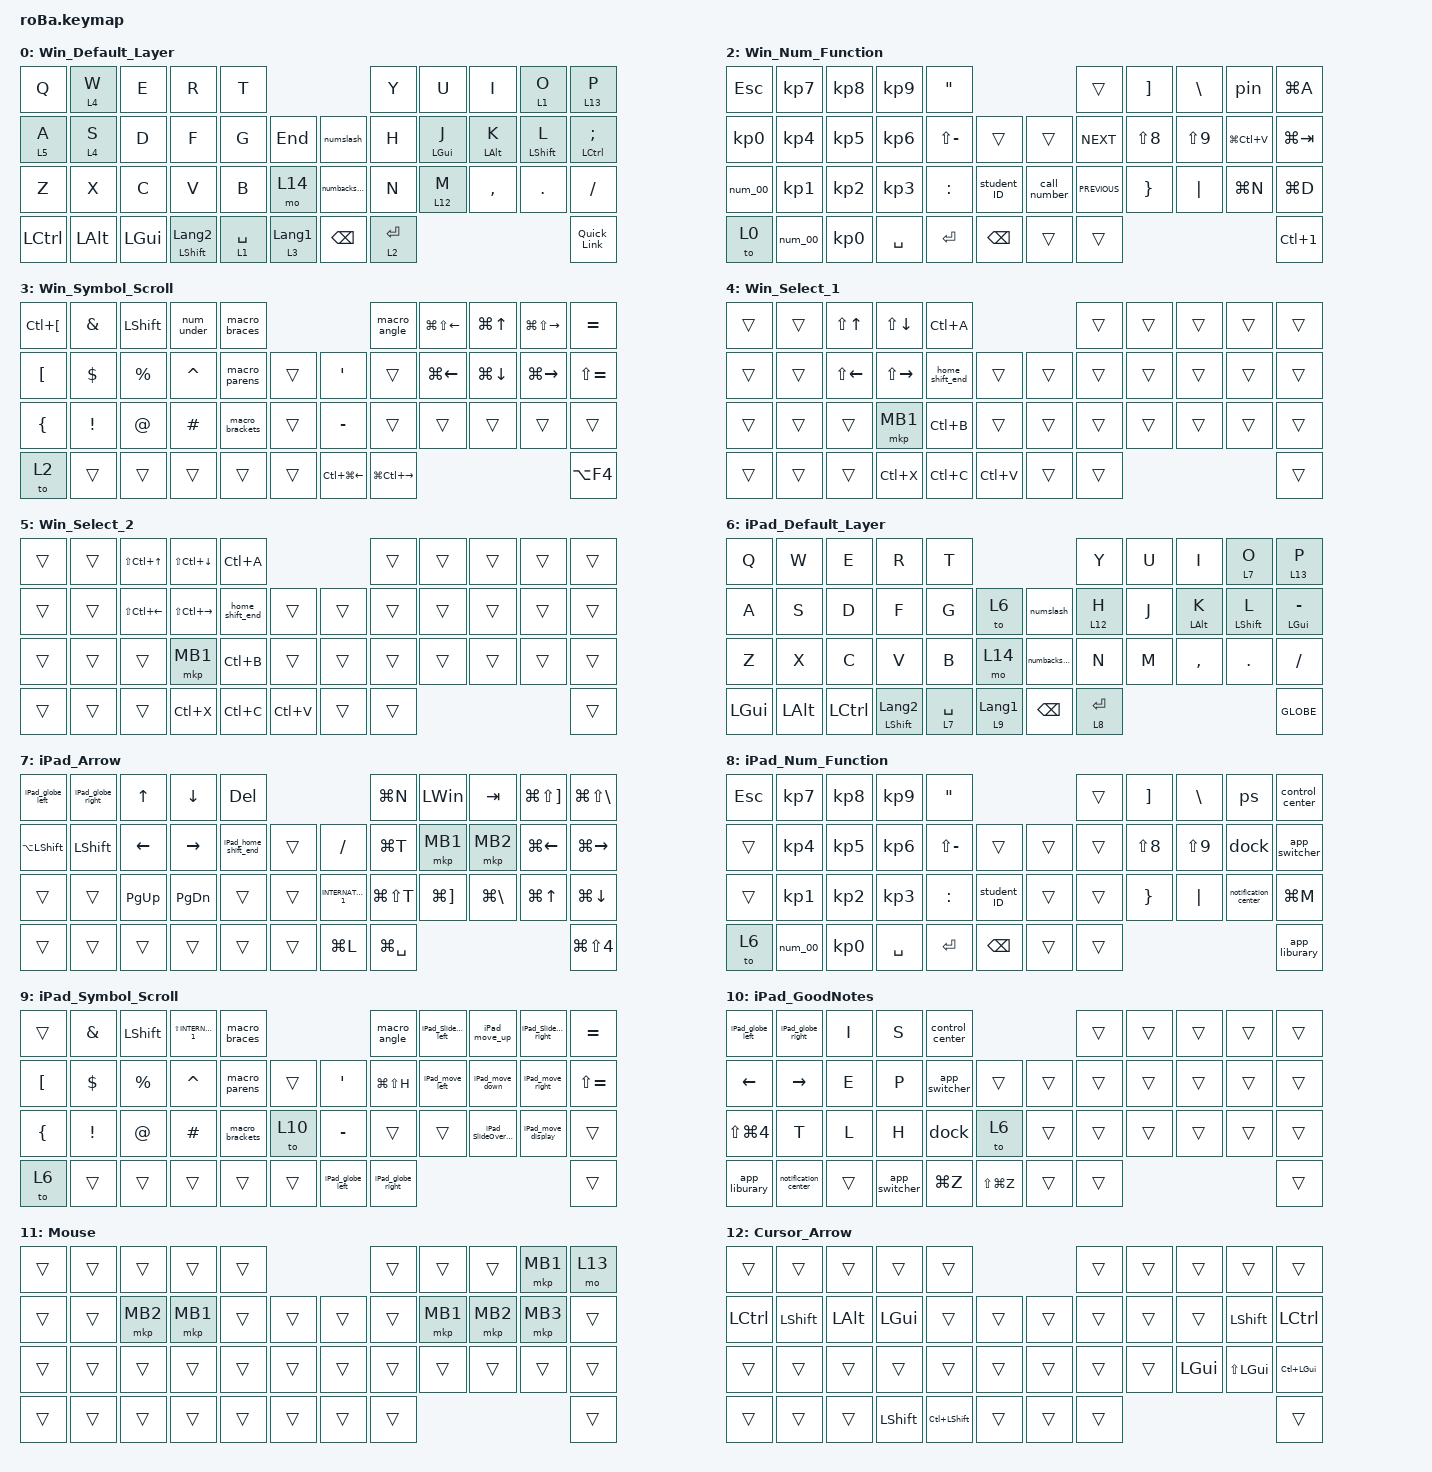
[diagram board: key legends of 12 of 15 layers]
#include <behaviors.dtsi>
#include <dt-bindings/zmk/bt.h>
#include <dt-bindings/zmk/keys.h>
#include <dt-bindings/zmk/pointing.h>

// #includeのあとのあたりにスクロール量変更の定義を追記

#define ZMK_POINTING_DEFAULT_SCRL_VAL 80

&mt {
    flavor = "balanced";
    quick-tap-ms = <0>;
};

&trackball {
    scroll-layers = <13>;

    arrows {
        layers = <12>;
        bindings =
            <&kp RIGHT_ARROW>,
            <&kp LEFT_ARROW>,
            <&kp UP_ARROW>,
            <&kp DOWN_ARROW>;

        wait-ms = <5>;
        tap-ms = <5>;
    };
};

/ {
    combos {
        compatible = "zmk,combos";

        shift_tab {
            bindings = <&kp LS(TAB)>;
            key-positions = <12 11>;
        };

        ctrl_alt_up {
            bindings = <&kp LC(LA(UP_ARROW))>;
            key-positions = <39 2>;
        };

        ctrl_alt_down {
            bindings = <&kp LC(LA(DOWN_ARROW))>;
            key-positions = <39 3>;
        };

        alt_z {
            bindings = <&kp LA(Z)>;
            key-positions = <22 23>;
        };

        left {
            bindings = <&left>;
            key-positions = <18 40>;
        };

        right {
            bindings = <&right>;
            key-positions = <19 40>;
        };

        up {
            bindings = <&up>;
            key-positions = <7 40>;
        };

        down {
            bindings = <&down>;
            key-positions = <6 40>;
        };

        tab {
            bindings = <&kp TAB>;
            key-positions = <13 12>;
        };

        to_cursor_arrow {
            bindings = <&mo 12>;
            key-positions = <18 19>;
        };

        raycast {
            timeout-ms = <25>;
            require-prior-idle-ms = <200>;
            bindings = <&kp LA(R)>;
            key-positions = <38 41>;
        };

        win_L {
            bindings = <&kp LG(L)>;
            key-positions = <41 21>;
        };

        alt_d {
            bindings = <&kp LA(D)>;
            key-positions = <39 40>;
        };

        stop_music {
            timeout-ms = <25>;
            require-prior-idle-ms = <200>;
            bindings = <&kp C_PLAY_PAUSE>;
            key-positions = <17 29>;
        };

        clipboard_history {
            bindings = <&kp LA(LS(V))>;
            key-positions = <24 23>;
        };

        f2 {
            bindings = <&kp F2>;
            key-positions = <41 37>;
        };

        win_v {
            bindings = <&kp LG(V)>;
            key-positions = <24 25>;
        };

        LaTeX_formula {
            bindings = <&LaTeX_formula>;
            key-positions = <39 11>;
        };

        time_schedule {
            bindings = <&kp LC(LA(LG(C)))>;
            key-positions = <21 18>;
        };

        back {
            bindings = <&kp LA(LEFT_ARROW)>;
            key-positions = <41 18>;
        };

        next {
            bindings = <&kp LA(RIGHT)>;
            key-positions = <19 41>;
        };
    };

    macros {
        to_layer_0: to_layer_0 {
            compatible = "zmk,behavior-macro-one-param";
            #binding-cells = <1>;
            bindings = <&to 0 &macro_param_1to1 &kp MACRO_PLACEHOLDER>;
            label = "TO_LAYER_0";
        };

        num_00: num_00 {
            compatible = "zmk,behavior-macro";
            #binding-cells = <0>;
            bindings = <&kp KP_NUMBER_0 &kp KP_NUMBER_0>;
            label = "NUM_00";
        };

        macro_parens: macro_parens {
            compatible = "zmk,behavior-macro";
            #binding-cells = <0>;
            bindings = <&kp LS(NUMBER_8) &kp LS(NUMBER_9) &kp LEFT>;
            label = "MACRO_PARENS";
        };

        macro_braces: macro_braces {
            compatible = "zmk,behavior-macro";
            #binding-cells = <0>;
            bindings = <&kp RIGHT_BRACKET &kp BACKSLASH &kp LEFT_ARROW>;
            label = "MACRO_BRACES";
        };

        macro_brackets: macro_brackets {
            compatible = "zmk,behavior-macro";
            #binding-cells = <0>;
            bindings = <&kp RIGHT_BRACE &kp PIPE &kp LEFT_ARROW>;
            label = "MACRO_BRACKETS";
        };

        macro_angle: macro_angle {
            compatible = "zmk,behavior-macro";
            #binding-cells = <0>;
            bindings = <&kp LESS_THAN &kp GREATER_THAN &kp LEFT>;
            label = "MACRO_ANGLE";
        };

        left: left {
            compatible = "zmk,behavior-macro";
            #binding-cells = <0>;
            bindings = <&kp LANGUAGE_1 &kp Z &kp H &kp SPACE>;
            label = "LEFT";
        };

        right: right {
            compatible = "zmk,behavior-macro";
            #binding-cells = <0>;
            bindings = <&kp LANGUAGE_1 &kp Z &kp L &kp SPACE>;
            label = "RIGHT";
        };

        up: up {
            compatible = "zmk,behavior-macro";
            #binding-cells = <0>;
            bindings = <&kp LANGUAGE_1 &kp Z &kp K &kp SPACE>;
            label = "UP";
        };

        down: down {
            compatible = "zmk,behavior-macro";
            #binding-cells = <0>;
            bindings = <&kp LANGUAGE_1 &kp Z &kp J &kp SPACE>;
            label = "DOWN";
        };

        numslash: new_macro {
            compatible = "zmk,behavior-macro";
            #binding-cells = <0>;
            bindings = <&kp LANGUAGE_2 &kp SLASH>;
            label = "NEW_MACRO";
        };

        numbackslash: numbackslash {
            compatible = "zmk,behavior-macro";
            #binding-cells = <0>;
            bindings = <&kp LANGUAGE_2 &kp INTERNATIONAL_1>;
            label = "NUMBACKSLASH";
        };

        bt0: bt0 {
            compatible = "zmk,behavior-macro";
            #binding-cells = <0>;
            bindings =
                <&tog_off 6 &tog_off 7 &tog_off 8 &tog_off 9 &tog_off 10>,
                <&macro_wait_time 200>,
                <&bt BT_SEL 0>,
                <&macro_wait_time 500>;

            label = "BT0";
        };

        bt1: bt1 {
            compatible = "zmk,behavior-macro";
            #binding-cells = <0>;
            bindings =
                <&tog_off 6 &tog_off 7 &tog_off 8 &tog_off 9 &tog_off 10>,
                <&macro_wait_time 200>,
                <&bt BT_SEL 1>,
                <&macro_wait_time 500>,
                <&tog_on 6>;

            label = "BT1";
        };

        bt2: bt2 {
            compatible = "zmk,behavior-macro";
            #binding-cells = <0>;
            bindings =
                <&tog_off 6 &tog_off 7 &tog_off 8 &tog_off 9 &tog_off 10>,
                <&macro_wait_time 200>,
                <&bt BT_SEL 2>,
                <&macro_wait_time 500>,
                <&tog_on 6>;

            label = "BT2";
        };

        bt3: bt3 {
            compatible = "zmk,behavior-macro";
            #binding-cells = <0>;
            bindings =
                <&tog_off 6 &tog_off 7 &tog_off 8 &tog_off 9 &tog_off 10>,
                <&macro_wait_time 200>,
                <&bt BT_SEL 3>,
                <&macro_wait_time 500>;

            label = "BT3";
        };

        Quick_Link: Quick_Link {
            compatible = "zmk,behavior-macro";
            #binding-cells = <0>;
            bindings = <&kp LG(X) &kp LANGUAGE_2>;
            label = "QUICK_LINK";
        };

        iPad_globe_left: globe_left {
            compatible = "zmk,behavior-macro";
            #binding-cells = <0>;
            bindings =
                <&macro_press>,
                <&kp GLOBE>,
                <&macro_tap>,
                <&kp LEFT_ARROW>,
                <&macro_release>,
                <&kp GLOBE>;

            label = "GLOBE_LEFT";
        };

        iPad_globe_right: globe_right {
            compatible = "zmk,behavior-macro";
            #binding-cells = <0>;
            bindings =
                <&macro_press>,
                <&kp GLOBE>,
                <&macro_tap>,
                <&kp RIGHT>,
                <&macro_release>,
                <&kp GLOBE>;

            label = "GLOBE_RIGHT";
        };

        iPad_move_left: iPad_move_left {
            compatible = "zmk,behavior-macro";
            #binding-cells = <0>;
            bindings =
                <&macro_press>,
                <&kp LCTRL &kp LEFT_SHIFT &kp GLOBE>,
                <&macro_tap>,
                <&kp LEFT_ARROW>,
                <&macro_release>,
                <&kp GLOBE &kp LEFT_SHIFT &kp LEFT_CONTROL>;

            label = "IPAD_MOVE_LEFT";
        };

        iPad_move_right: iPad_move_right {
            compatible = "zmk,behavior-macro";
            #binding-cells = <0>;
            bindings =
                <&macro_press>,
                <&kp LCTRL &kp LEFT_SHIFT &kp GLOBE>,
                <&macro_tap>,
                <&kp RIGHT>,
                <&macro_release>,
                <&kp GLOBE &kp LEFT_SHIFT &kp LEFT_CONTROL>;

            label = "IPAD_MOVE_RIGHT";
        };

        iPad_move_up: iPad_move_up {
            compatible = "zmk,behavior-macro";
            #binding-cells = <0>;
            bindings =
                <&macro_press>,
                <&kp LCTRL &kp LEFT_SHIFT &kp GLOBE>,
                <&macro_tap>,
                <&kp UP_ARROW>,
                <&macro_release>,
                <&kp GLOBE &kp LEFT_SHIFT &kp LEFT_CONTROL>;

            label = "IPAD_MOVE_UP";
        };

        iPad_move_down: iPad_move_down {
            compatible = "zmk,behavior-macro";
            #binding-cells = <0>;
            bindings =
                <&macro_press>,
                <&kp LCTRL &kp LEFT_SHIFT &kp GLOBE>,
                <&macro_tap>,
                <&kp DOWN>,
                <&macro_release>,
                <&kp GLOBE &kp LEFT_SHIFT &kp LEFT_CONTROL>;

            label = "IPAD_MOVE_DOWN";
        };

        iPad_SlideOvere_left: iPad_SlideOvere_left {
            compatible = "zmk,behavior-macro";
            #binding-cells = <0>;
            bindings =
                <&macro_press>,
                <&kp LEFT_ALT &kp GLOBE>,
                <&macro_tap>,
                <&kp LEFT_ARROW>,
                <&macro_release>,
                <&kp GLOBE &kp LEFT_ALT>;

            label = "IPAD_SLIDEOVERE_LEFT";
        };

        iPad_SlideOvere_right: iPad_SlideOvere_right {
            compatible = "zmk,behavior-macro";
            #binding-cells = <0>;
            bindings =
                <&macro_press>,
                <&kp LEFT_ALT &kp GLOBE>,
                <&macro_tap>,
                <&kp RIGHT>,
                <&macro_release>,
                <&kp GLOBE &kp LEFT_ALT>;

            label = "IPAD_SLIDEOVERE_RIGHT";
        };

        iPad_SlideOvere_Non: iPad_SlideOvere_Non {
            compatible = "zmk,behavior-macro";
            #binding-cells = <0>;
            bindings =
                <&macro_press>,
                <&kp GLOBE>,
                <&macro_tap>,
                <&kp INTERNATIONAL_1>,
                <&macro_release>,
                <&kp GLOBE>;

            label = "IPAD_SLIDEOVERE_NON";
        };

        iPad_move_display: iPad_move_display {
            compatible = "zmk,behavior-macro";
            #binding-cells = <0>;
            bindings =
                <&macro_press>,
                <&kp LCTRL &kp GLOBE>,
                <&macro_tap>,
                <&kp INTERNATIONAL_1>,
                <&macro_release>,
                <&kp GLOBE &kp LEFT_CONTROL>;

            label = "IPAD_MOVE_DISPLAY";
        };

        home_shift_end: home_shift_end {
            compatible = "zmk,behavior-macro";
            #binding-cells = <0>;
            bindings = <&kp HOME &kp LS(END)>;
            label = "HOME_SHIFT_END";
        };

        num_under: num_under {
            compatible = "zmk,behavior-macro";
            #binding-cells = <0>;
            bindings = <&kp LANGUAGE_2 &kp LS(INTERNATIONAL_1)>;
            label = "NUM_UNDER";
        };

        pin: pin {
            compatible = "zmk,behavior-macro";
            #binding-cells = <0>;
            bindings = <&kp NUMBER_1 &kp NUMBER_1 &kp N5 &kp NUMBER_4 &kp NUMBER_3>;
            label = "PIN";
        };

        ps: ps {
            compatible = "zmk,behavior-macro";
            #binding-cells = <0>;
            bindings = <&kp N0 &kp N7 &kp N0 &kp N5 &kp N8 &kp NUMBER_4>;
            label = "PS";
        };

        home_shift_end_ipad: home_shift_end_ipad {
            compatible = "zmk,behavior-macro";
            #binding-cells = <0>;
            bindings = <&kp LS(LEFT) &kp RS(LS(RIGHT))>;
            label = "HOME_SHIFT_END_IPAD";
        };

        ZMK: ZMK {
            compatible = "zmk,behavior-macro";
            #binding-cells = <0>;
            bindings = <&kp LC(T) &kp LANGUAGE_2 &kp Z &kp M &kp K &kp ENTER>;
            label = "ZMK";
        };

        iPad_home_shift_end: iPad_home_shift_end {
            compatible = "zmk,behavior-macro";
            #binding-cells = <0>;
            bindings = <&kp LG(LEFT_ARROW) &kp LS(LG(RIGHT))>;
            label = "IPAD_HOME_SHIFT_END";
        };

        student_ID: student_ID {
            compatible = "zmk,behavior-macro";
            #binding-cells = <0>;
            bindings = <&kp KP_NUMBER_2 &kp KP_NUMBER_4 &kp KP_NUMBER_1 &kp KP_NUMBER_2 &kp KP_NUMBER_6 &kp KP_NUMBER_4 &kp KP_NUMBER_9>;
            label = "STUDENT_ID";
        };

        drive_new_folder: drive_new_folder {
            compatible = "zmk,behavior-macro";
            #binding-cells = <0>;
            bindings =
                <&macro_press>,
                <&kp LEFT_ALT>,
                <&macro_tap>,
                <&kp C>,
                <&macro_release>,
                <&kp LEFT_ALT>,
                <&macro_wait_time 20>,
                <&macro_tap>,
                <&kp F>;

            label = "DRIVE_NEW_FOLDER";
        };

        ctrl_scroll_down: ctrl_scroll_down {
            compatible = "zmk,behavior-macro";
            #binding-cells = <0>;
            wait-ms = <0>;
            tap-ms = <20>;
            bindings =
                <&macro_press>,
                <&kp LCTRL>,
                <&macro_tap>,
                <&msc SCRL_DOWN>,
                <&macro_release>,
                <&kp LCTRL>;
        };

        ctrl_scroll_up: ctrl_scroll_up {
            compatible = "zmk,behavior-macro";
            #binding-cells = <0>;
            wait-ms = <0>;
            tap-ms = <20>;
            bindings =
                <&macro_press>,
                <&kp LCTRL>,
                <&macro_tap>,
                <&msc SCRL_UP>,
                <&macro_release>,
                <&kp LCTRL>;
        };

        call_number: call_number {
            compatible = "zmk,behavior-macro";
            #binding-cells = <0>;
            bindings = <&kp KP_NUMBER_0 &kp KP_NUMBER_7 &kp KP_NUMBER_0 &kp KP_NUMBER_9 &kp KP_NUMBER_0 &kp KP_NUMBER_9 &kp KP_NUMBER_2 &kp KP_NUMBER_0 &kp KP_NUMBER_6 &kp KP_NUMBER_7 &kp KP_NUMBER_3>;
            label = "CALL_NUMBER";
        };

        LaTeX_formula: LaTeX_formula {
            compatible = "zmk,behavior-macro";
            #binding-cells = <0>;
            bindings = <&kp LANGUAGE_2 &kp DOLLAR &kp DOLLAR &kp LEFT_ARROW>;
            label = "LATEX_FORMULA";
        };

        app_switcher: app_switcher {
            compatible = "zmk,behavior-macro";
            #binding-cells = <0>;
            bindings =
                <&macro_press>,
                <&kp GLOBE>,
                <&macro_tap>,
                <&kp UP_ARROW>,
                <&macro_release>,
                <&kp GLOBE>;

            label = "APP_SWITCHER";
        };

        dock: dock {
            compatible = "zmk,behavior-macro";
            #binding-cells = <0>;
            bindings =
                <&macro_press>,
                <&kp GLOBE>,
                <&macro_tap>,
                <&kp A>,
                <&macro_release>,
                <&kp GLOBE>;

            label = "DOCK";
        };

        control_center: control_center {
            compatible = "zmk,behavior-macro";
            #binding-cells = <0>;
            bindings =
                <&macro_press>,
                <&kp GLOBE>,
                <&macro_tap>,
                <&kp C>,
                <&macro_release>,
                <&kp GLOBE>;

            label = "CONTROL_CENTER";
        };

        notification_center: notification_center {
            compatible = "zmk,behavior-macro";
            #binding-cells = <0>;
            bindings =
                <&macro_press>,
                <&kp GLOBE>,
                <&macro_tap>,
                <&kp N>,
                <&macro_release>,
                <&kp GLOBE>;

            label = "NOTIFICATION_CENTER";
        };

        app_liburary: app_liburary {
            compatible = "zmk,behavior-macro";
            #binding-cells = <0>;
            bindings =
                <&macro_press>,
                <&kp LEFT_SHIFT &kp GLOBE>,
                <&macro_tap>,
                <&kp A>,
                <&macro_release>,
                <&kp GLOBE &kp LEFT_SHIFT>;

            label = "APP_LIBURARY";
        };
    };

    behaviors {
        lt_to_layer_0: lt_to_layer_0 {
            compatible = "zmk,behavior-hold-tap";
            label = "LAYER_TAP_TO_0";
            bindings = <&mo>, <&to_layer_0>;

            #binding-cells = <2>;
            tapping-term-ms = <200>;
        };

        // スクロール方向を逆にしたい場合は <&msc SCRL_DOWN> と <&msc SCRL_UP> を入れ替えてください

        encoder_msc_down_up: encoder_msc_down_up {
            compatible = "zmk,behavior-sensor-rotate";
            label = "ENCODER_MSC_DOWN_UP";
            #sensor-binding-cells = <0>;
            bindings = <&msc SCRL_DOWN>, <&msc SCRL_UP>;

            tap-ms = <20>;
        };

        encoder_ctrl_scroll_down_up: encoder_ctrl_scroll_down_up {
            compatible = "zmk,behavior-sensor-rotate";
            label = "ENCODER_CTRL_SCROLL_DOWN_UP";
            #sensor-binding-cells = <0>;
            bindings = <&ctrl_scroll_down>, <&ctrl_scroll_up>;

            tap-ms = <20>;
        };

        tog_on: toggle_layer_on_only {
            compatible = "zmk,behavior-toggle-layer";
            #binding-cells = <1>;
            display-name = "Toggle Layer On";
            toggle-mode = "on";
        };

        tog_off: toggle_layer_off_only {
            compatible = "zmk,behavior-toggle-layer";
            #binding-cells = <1>;
            display-name = "Toggle Layer Off";
            toggle-mode = "off";
        };

        dock_cntrl_center: dock_cntrl_center {
            compatible = "zmk,behavior-tap-dance";
            label = "DOCK_CNTRL_CENTER";
            #binding-cells = <0>;
            bindings = <&kp LG(LA(D))>, <&kp LG(LA(C))>;

            tapping-term-ms = <350>;
        };

        home_ctrl_home: home_ctrl_home {
            compatible = "zmk,behavior-tap-dance";
            label = "HOME_CTRL_HOME";
            #binding-cells = <0>;
            bindings = <&kp HOME>, <&kp LC(HOME)>;
        };

        end_ctrl_end: end_ctrl_end {
            compatible = "zmk,behavior-tap-dance";
            label = "END_CTRL_END";
            #binding-cells = <0>;
            bindings = <&kp END>, <&kp LC(END)>;
        };

        Esc_ctrl_1: Esc_ctrl_1 {
            compatible = "zmk,behavior-tap-dance";
            label = "ESC_CTRL_1";
            #binding-cells = <0>;
            bindings = <&kp ESCAPE>, <&kp LC(NUMBER_1)>;
        };

        doller: doller {
            compatible = "zmk,behavior-tap-dance";
            label = "DOLLER";
            #binding-cells = <0>;
            bindings = <&kp DOLLAR>, <&LaTeX_formula>;
        };
    };

    // 設定したいレイヤーに sensor-bindings = <&encoder_msc_down_up>; を追記
    // 以下は実際にレイヤー０に追記した例

    keymap {
        compatible = "zmk,keymap";

        Win_Default_Layer {
            bindings = <
&kp Q      &lt 4 W       &kp E         &kp R                      &kp T                                             &kp Y        &kp U           &kp I           &lt 1 O           &lt 13 P
&lt 5 A    &lt 4 S       &kp D         &kp F                      &kp G        &kp END               &numslash      &kp H        &mt LEFT_GUI J  &mt LEFT_ALT K  &mt LEFT_SHIFT L  &mt LCTRL SEMICOLON
&kp Z      &kp X         &kp C         &kp V                      &kp B        &mo 14                &numbackslash  &kp N        &lt 12 M        &kp COMMA       &kp DOT           &kp SLASH
&kp LCTRL  &kp LEFT_ALT  &kp LEFT_GUI  &mt LEFT_SHIFT LANGUAGE_2  &lt 1 SPACE  &lt 3 LANGUAGE_1      &kp BACKSPACE  &lt 2 ENTER                                                    &Quick_Link
            >;

            // sensor-bindings = <&inc_dec_kp PG_UP PAGE_DOWN>;

            sensor-bindings = <&encoder_msc_down_up>;
        };

        Win_Arrow {
            bindings = <
&kp LA(TAB)           &kp LC(TAB)    &kp UP_ARROW             &kp DOWN_ARROW       &kp DEL                                         &kp LC(N)      &kp LEFT_ALT   &kp TAB            &kp LC(PAGE_UP)  &kp LC(PAGE_DOWN)
&kp LA(LS(N5))        &kp LA(S)      &mt LC(LEFT) LEFT_ARROW  &mt LC(RIGHT) RIGHT  &trans         &trans      &kp SLASH            &kp LC(T)      &mkp MB1       &kp LC(LA(LG(D)))  &home_ctrl_home  &end_ctrl_end
&kp LC(LEFT_BRACKET)  &kp LC(SLASH)  &drive_new_folder        &kp LC(LS(N))        &kp LG(LC(T))  &trans      &kp INTERNATIONAL_1  &kp LS(LC(T))  &kp LA(LS(D))  &trans             &trans           &trans
&trans                &trans         &trans                   &trans               &trans         &trans      &kp F8               &kp F7                                                            &kp LG(LS(S))
            >;

            sensor-bindings = <&inc_dec_kp C_VOLUME_DOWN C_VOLUME_UP>;
        };

        Win_Num_Function {
            bindings = <
&kp ESCAPE  &kp KP_NUMBER_7  &kp KP_NUMBER_8  &kp KP_NUMBER_9  &kp DOUBLE_QUOTES                                   &trans          &kp RIGHT_BRACKET  &kp BACKSLASH  &pin           &kp LG(A)
&kp KP_N0   &kp KP_NUMBER_4  &kp KP_NUMBER_5  &kp KP_NUMBER_6  &kp LS(MINUS)      &trans             &trans        &kp C_NEXT      &kp LS(N8)         &kp LS(N9)     &kp LG(LC(V))  &kp LG(TAB)
&num_00     &kp KP_NUMBER_1  &kp KP_NUMBER_2  &kp KP_NUMBER_3  &kp COLON          &student_ID        &call_number  &kp C_PREVIOUS  &kp RIGHT_BRACE    &kp PIPE       &kp LG(N)      &kp LG(D)
&to 0       &num_00          &kp KP_NUMBER_0  &kp SPACE        &kp ENTER          &kp BACKSPACE      &trans        &trans                                                           &kp LC(NUMBER_1)
            >;

            sensor-bindings = <&inc_dec_kp END HOME>;
        };

        Win_Symbol_Scroll {
            bindings = <
&kp LC(LEFT_BRACKET)  &kp AMPERSAND    &kp LEFT_SHIFT  &num_under  &macro_braces                                        &macro_angle       &kp LG(LS(LEFT))    &kp LG(UP_ARROW)    &kp LG(LS(RIGHT))    &kp EQUAL
&kp LEFT_BRACKET      &kp DOLLAR       &kp PERCENT     &kp CARET   &macro_parens    &trans      &kp APOS                &trans             &kp LG(LEFT_ARROW)  &kp LG(DOWN_ARROW)  &kp LG(RIGHT_ARROW)  &kp LS(EQUAL)
&kp LEFT_BRACE        &kp EXCLAMATION  &kp AT          &kp HASH    &macro_brackets  &trans      &kp MINUS               &trans             &trans              &trans              &trans               &trans
&to 2                 &trans           &trans          &trans      &trans           &trans      &kp LC(LG(LEFT_ARROW))  &kp LG(LC(RIGHT))                                                               &kp LA(F4)
            >;

            sensor-bindings = <&encoder_ctrl_scroll_down_up>;
        };

        Win_Select_1 {
            bindings = <
&trans  &trans  &kp LS(UP_ARROW)    &kp LS(DOWN_ARROW)  &kp LC(A)                               &trans  &trans  &trans  &trans  &trans
&trans  &trans  &kp LS(LEFT_ARROW)  &kp LS(RIGHT)       &home_shift_end  &trans         &trans  &trans  &trans  &trans  &trans  &trans
&trans  &trans  &trans              &mkp MB1            &kp LC(B)        &trans         &trans  &trans  &trans  &trans  &trans  &trans
&trans  &trans  &trans              &kp LC(X)           &kp LC(C)        &kp LC(V)      &trans  &trans                          &trans
            >;
        };

        Win_Select_2 {
            bindings = <
&trans  &trans  &kp LS(LC(UP_ARROW))  &kp LS(LC(DOWN_ARROW))  &kp LC(A)                               &trans  &trans  &trans  &trans  &trans
&trans  &trans  &kp LS(LC(LEFT))      &kp LS(LC(RIGHT))       &home_shift_end  &trans         &trans  &trans  &trans  &trans  &trans  &trans
&trans  &trans  &trans                &mkp MB1                &kp LC(B)        &trans         &trans  &trans  &trans  &trans  &trans  &trans
&trans  &trans  &trans                &kp LC(X)               &kp LC(C)        &kp LC(V)      &trans  &trans                          &trans
            >;
        };

        iPad_Default_Layer {
            bindings = <
&kp Q     &kp W     &kp E      &kp R                      &kp T                                             &kp Y        &kp U  &kp I           &lt 7 O           &lt 13 P
&kp A     &kp S     &kp D      &kp F                      &kp G        &to 6                 &numslash      &lt 12 H     &kp J  &mt LEFT_ALT K  &mt LEFT_SHIFT L  &mt LEFT_GUI MINUS
&kp Z     &kp X     &kp C      &kp V                      &kp B        &mo 14                &numbackslash  &kp N        &kp M  &kp COMMA       &kp DOT           &kp FSLH
&kp LGUI  &kp LALT  &kp LCTRL  &mt LEFT_SHIFT LANGUAGE_2  &lt 7 SPACE  &lt 9 LANGUAGE_1      &kp BSPC       &lt 8 ENTER                                           &kp GLOBE
            >;

            // sensor-bindings = <&inc_dec_kp PG_UP PAGE_DOWN>;

            sensor-bindings = <&encoder_msc_down_up>;
        };

        iPad_Arrow {
            bindings = <
&iPad_globe_left    &iPad_globe_right  &kp UP_ARROW  &kp DOWN_ARROW  &kp DEL                                                &kp LG(N)      &kp LEFT_WIN           &kp TAB            &kp LG(LS(RIGHT_BRACKET))  &kp LG(LS(BACKSLASH))
&kp LA(LEFT_SHIFT)  &kp LSHIFT         &kp LEFT      &kp RIGHT       &iPad_home_shift_end  &trans      &kp SLASH            &kp LG(T)      &mkp MB1               &mkp MB2           &kp LG(LEFT)               &kp LG(RIGHT_ARROW)
&trans              &trans             &kp PG_UP     &kp PAGE_DOWN   &trans                &trans      &kp INTERNATIONAL_1  &kp LG(LS(T))  &kp LG(RIGHT_BRACKET)  &kp LG(BACKSLASH)  &kp LG(UP_ARROW)           &kp LG(DOWN)
&trans              &trans             &trans        &trans          &trans                &trans      &kp LG(L)            &kp LG(SPACE)                                                                       &kp LG(LS(NUMBER_4))
            >;

            sensor-bindings = <&inc_dec_kp C_VOLUME_DOWN C_VOLUME_UP>;
        };

        iPad_Num_Function {
            bindings = <
&kp ESCAPE  &kp KP_NUMBER_7  &kp KP_NUMBER_8  &kp KP_NUMBER_9  &kp DOUBLE_QUOTES                             &trans  &kp RIGHT_BRACKET  &kp BACKSLASH  &ps                   &control_center
&trans      &kp KP_NUMBER_4  &kp KP_NUMBER_5  &kp KP_NUMBER_6  &kp LS(MINUS)      &trans             &trans  &trans  &kp LS(N8)         &kp LS(N9)     &dock                 &app_switcher
&trans      &kp KP_NUMBER_1  &kp KP_NUMBER_2  &kp KP_NUMBER_3  &kp COLON          &student_ID        &trans  &trans  &kp RIGHT_BRACE    &kp PIPE       &notification_center  &kp LG(M)
&to 6       &num_00          &kp KP_NUMBER_0  &kp SPACE        &kp ENTER          &kp BACKSPACE      &trans  &trans                                                          &app_liburary
            >;
        };

        iPad_Symbol_Scroll {
            bindings = <
&trans            &kp AMPERSAND    &kp LEFT_SHIFT  &kp LS(INTERNATIONAL_1)  &macro_braces                                  &macro_angle       &iPad_SlideOvere_left  &iPad_move_up         &iPad_SlideOvere_right  &kp EQUAL
&kp LEFT_BRACKET  &kp DOLLAR       &kp PERCENT     &kp CARET                &macro_parens    &trans      &kp APOS          &kp LG(LS(H))      &iPad_move_left        &iPad_move_down       &iPad_move_right        &kp LS(EQUAL)
&kp LEFT_BRACE    &kp EXCLAMATION  &kp AT          &kp HASH                 &macro_brackets  &to 10      &kp MINUS         &trans             &trans                 &iPad_SlideOvere_Non  &iPad_move_display      &trans
&to 6             &trans           &trans          &trans                   &trans           &trans      &iPad_globe_left  &iPad_globe_right                                                                       &trans
            >;

            sensor-bindings = <&inc_dec_kp LC(PAGE_UP) LC(PAGE_DOWN)>;
        };

        iPad_GoodNotes {
            bindings = <
&iPad_globe_left      &iPad_globe_right     &kp I   &kp S          &control_center                             &trans  &trans  &trans  &trans  &trans
&kp LEFT              &kp RIGHT             &kp E   &kp P          &app_switcher    &trans             &trans  &trans  &trans  &trans  &trans  &trans
&kp LS(LG(NUMBER_4))  &kp T                 &kp L   &kp H          &dock            &to 6              &trans  &trans  &trans  &trans  &trans  &trans
&app_liburary         &notification_center  &trans  &app_switcher  &kp LG(Z)        &kp LS(LG(Z))      &trans  &trans                          &trans
            >;

            sensor-bindings = <&encoder_msc_down_up>;
        };

        Mouse {
            bindings = <
&trans  &trans  &trans    &trans    &trans                      &trans  &trans    &trans    &mkp MB1  &mo 13
&trans  &trans  &mkp MB2  &mkp MB1  &trans  &trans      &trans  &trans  &mkp MB1  &mkp MB2  &mkp MB3  &trans
&trans  &trans  &trans    &trans    &trans  &trans      &trans  &trans  &trans    &trans    &trans    &trans
&trans  &trans  &trans    &trans    &trans  &trans      &trans  &trans                                &trans
            >;
        };

        Cursor_Arrow {
            bindings = <
&trans            &trans          &trans        &trans          &trans                                  &trans  &trans  &trans        &trans            &trans
&kp LEFT_CONTROL  &kp LEFT_SHIFT  &kp LEFT_ALT  &kp LEFT_GUI    &trans              &trans      &trans  &trans  &trans  &trans        &kp LEFT_SHIFT    &kp LCTRL
&trans            &trans          &trans        &trans          &trans              &trans      &trans  &trans  &trans  &kp LEFT_GUI  &kp LS(LEFT_GUI)  &kp LC(LEFT_GUI)
&trans            &trans          &trans        &kp LEFT_SHIFT  &kp LC(LEFT_SHIFT)  &trans      &trans  &trans                                          &trans
            >;
        };

        Scroll {
            bindings = <
&trans  &trans  &trans  &trans  &trans                      &trans  &trans  &trans  &kp LCTRL  &trans
&trans  &trans  &trans  &trans  &trans  &trans      &trans  &trans  &trans  &trans  &trans     &trans
&trans  &trans  &trans  &trans  &trans  &trans      &trans  &trans  &trans  &trans  &trans     &trans
&trans  &trans  &trans  &trans  &trans  &trans      &trans  &trans                             &trans
            >;
        };

        Bluetooth {
            bindings = <
&trans  &trans        &trans        &trans        &trans                           &bt0    &bt1    &bt2    &bt3    &bt BT_SEL 4
&trans  &trans        &trans        &trans        &trans  &trans      &trans       &trans  &trans  &trans  &trans  &trans
&trans  &kp NUMBER_1  &kp NUMBER_2  &kp NUMBER_3  &trans  &trans      &bootloader  &trans  &trans  &trans  &trans  &bt BT_CLR
&trans  &trans        &trans        &trans        &trans  &trans      &trans       &ZMK                            &bt BT_CLR_ALL
            >;
        };
    };
};
